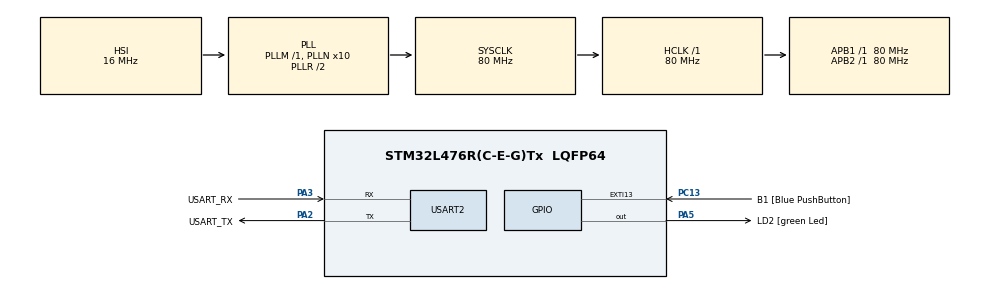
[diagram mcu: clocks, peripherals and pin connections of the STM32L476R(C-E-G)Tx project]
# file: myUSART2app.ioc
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Dma.Request0=USART2_RX
Dma.Request1=USART2_TX
Dma.USART2_RX.0.Direction=DMA_PERIPH_TO_MEMORY
Dma.USART2_RX.0.Instance=DMA1_Channel6
Dma.USART2_RX.0.MemDataAlignment=DMA_MDATAALIGN_BYTE
Dma.USART2_RX.0.MemInc=DMA_MINC_ENABLE
Dma.USART2_RX.0.Mode=DMA_NORMAL
Dma.USART2_RX.0.PeriphDataAlignment=DMA_PDATAALIGN_BYTE
Dma.USART2_RX.0.PeriphInc=DMA_PINC_DISABLE
Dma.USART2_RX.0.Priority=DMA_PRIORITY_LOW
Dma.USART2_TX.1.Direction=DMA_MEMORY_TO_PERIPH
Dma.USART2_TX.1.Instance=DMA1_Channel7
Dma.USART2_TX.1.MemDataAlignment=DMA_MDATAALIGN_BYTE
Dma.USART2_TX.1.MemInc=DMA_MINC_ENABLE
Dma.USART2_TX.1.Mode=DMA_NORMAL
Dma.USART2_TX.1.PeriphDataAlignment=DMA_PDATAALIGN_BYTE
Dma.USART2_TX.1.PeriphInc=DMA_PINC_DISABLE
Dma.USART2_TX.1.Priority=DMA_PRIORITY_LOW
Mcu.Family=STM32L4
Mcu.Name=STM32L476R(C-E-G)Tx
Mcu.Package=LQFP64
NVIC.DMA1_Channel6_IRQn=true\:0\:0\:false\:false\:true\:false\:true
NVIC.DMA1_Channel7_IRQn=true\:0\:0\:false\:false\:true\:false\:true
NVIC.PriorityGroup=NVIC_PRIORITYGROUP_4
NVIC.USART2_IRQn=true\:0\:0\:false\:false\:true\:true\:true
PA13\ (JTMS-SWDIO).GPIO_Label=TMS
PA13\ (JTMS-SWDIO).Mode=Serial_Wire
PA13\ (JTMS-SWDIO).Signal=SYS_JTMS-SWDIO
PA14\ (JTCK-SWCLK).GPIO_Label=TCK
PA14\ (JTCK-SWCLK).Mode=Serial_Wire
PA14\ (JTCK-SWCLK).Signal=SYS_JTCK-SWCLK
PA2.GPIO_Label=USART_TX
PA2.GPIO_Mode=GPIO_MODE_AF_PP
PA2.GPIO_PuPd=GPIO_NOPULL
PA2.GPIO_Speed=GPIO_SPEED_FREQ_VERY_HIGH
PA2.Mode=Asynchronous
PA2.Signal=USART2_TX
PA3.GPIO_Label=USART_RX
PA3.GPIO_Mode=GPIO_MODE_AF_PP
PA3.GPIO_PuPd=GPIO_NOPULL
PA3.GPIO_Speed=GPIO_SPEED_FREQ_VERY_HIGH
PA3.Mode=Asynchronous
PA3.Signal=USART2_RX
PA5.GPIO_Label=LD2 [green Led]
PA5.GPIO_ModeDefaultOutputPP=GPIO_MODE_OUTPUT_PP
PA5.GPIO_PuPd=GPIO_NOPULL
PA5.GPIO_Speed=GPIO_SPEED_FREQ_LOW
PA5.Signal=GPIO_Output
PB3\ (JTDO-TRACESWO).GPIO_Label=SWO
PB3\ (JTDO-TRACESWO).Signal=SYS_JTDO-SWO
PC13.GPIO_Label=B1 [Blue PushButton]
PC13.GPIO_ModeDefaultEXTI=GPIO_MODE_IT_FALLING
PC13.GPIO_PuPd=GPIO_NOPULL
PC13.Signal=GPXTI13
PC14-OSC32_IN\ (PC14).Mode=LSE-External-Oscillator
PC14-OSC32_IN\ (PC14).Signal=RCC_OSC32_IN
PC15-OSC32_OUT\ (PC15).Mode=LSE-External-Oscillator
PC15-OSC32_OUT\ (PC15).Signal=RCC_OSC32_OUT
PH0-OSC_IN\ (PH0).Signal=RCC_OSC_IN
PH1-OSC_OUT\ (PH1).Signal=RCC_OSC_OUT
ProjectManager.HeapSize=0x200
ProjectManager.StackSize=0x400
ProjectManager.TargetToolchain=SW4STM32
RCC.ADCFreq_Value=64000000
RCC.AHBFreq_Value=80000000
RCC.APB1Freq_Value=80000000
RCC.APB1TimFreq_Value=80000000
RCC.APB2Freq_Value=80000000
RCC.APB2TimFreq_Value=80000000
RCC.CortexFreq_Value=80000000
RCC.HCLKFreq_Value=80000000
RCC.HSE_VALUE=8000000
RCC.HSI_VALUE=16000000
RCC.MSI_VALUE=4000000
RCC.PLLN=10
RCC.PLLSourceVirtual=RCC_PLLSOURCE_HSI
RCC.PREFETCH_ENABLE=1
RCC.SYSCLKFreq_VALUE=80000000
RCC.SYSCLKSource=RCC_SYSCLKSOURCE_PLLCLK
RCC.USBFreq_Value=64000000
RCC.VCOOutputFreq_Value=160000000
USART2.VirtualMode-Asynchronous=VM_ASYNC
board=NUCLEO-L476RG

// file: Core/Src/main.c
/* USER CODE BEGIN Header */
/**
  ******************************************************************************
  * @file           : main.c
  * @brief          : Escape the Island — Text RPG
  ******************************************************************************
  * Baud Rate = 115200
  ******************************************************************************
  */
/* USER CODE END Header */
#include "main.h"

/* USER CODE BEGIN Includes */
#include <string.h>
/* USER CODE END Includes */

/* USER CODE BEGIN PTD */

typedef enum { //keeps track of state
    STATE_MAIN_MENU = 0,
    STATE_CHAR_SELECT,
    STATE_DIFF_SELECT,
    STATE_EXPLORE,
    STATE_DIALOGUE,
    STATE_INVENTORY,
    STATE_PUZZLE,
	STATE_TRAVEL,
	STATE_JUNGLE,
	STATE_CAVE,
	STATE_COASTLINE,
	STATE_TOWER,
	STATE_BUNKER,
    STATE_GAME_OVER
} GameStateEnum;

typedef struct { //keeps track of status variables
    int8_t   health;        // 0-100, death at 0
    int8_t   fear;          // 0-100, collapse at 100
    int8_t   morale;        // 0-100, abandon at 0
    int8_t   starvation;    // 0-100, death at 100
    uint8_t  character;     // 0=Engineer 1=Medic 2=Survivalist 3=Skeptic
    uint8_t  difficulty;    // 0=Easy 1=Hard
    uint8_t  location;      // 0=Beach 1=Jungle 2=Cave 3=Coastline 4=Tower 5=Bunker
    uint8_t  day;
    uint8_t searches_done;
    uint8_t  inventory[8];  // 0=battery 1=wire 2=tools 3=map 4=rope 5=wood 6=knife 7=key
    uint16_t flags;
    uint8_t survivors[4]; // 1=present, 0=missing. 0=Engineer,1=Medic,2=Survivalist,3=Skeptic
    uint8_t notes[4];
    uint8_t  puzzles_solved;
    uint8_t puzzle_step;        // tracks progress through puzzle
    char    puzzle_input[8];    // stores player input
    uint8_t active_puzzle;      // 0=radio, 1=cave, 2=bunker
    GameStateEnum state;
    GameStateEnum prev_state;
    uint32_t rng_seed;
} GameState;

/* USER CODE END PTD */

/* USER CODE BEGIN PD */

#define FLAG_MET_ENGINEER    (1 << 0)
#define FLAG_MET_MEDIC       (1 << 1)
#define FLAG_MET_SURVIVALIST (1 << 2)
#define FLAG_MET_SKEPTIC     (1 << 3)
#define FLAG_FOUND_KEY       (1 << 4)
#define FLAG_FIRE_LIT        (1 << 5)
#define FLAG_RAFT_BUILT      (1 << 6)
#define FLAG_HIGH_FEAR       (1 << 7)
#define FLAG_ENGINEER_HINT  (1 << 8)

#define ITEM_BATTERY  0
#define ITEM_WIRE     1
#define ITEM_TOOLS    2
#define ITEM_MAP      3
#define ITEM_ROPE     4
#define ITEM_WOOD     5
#define ITEM_KNIFE    6
#define ITEM_KEY      7

/* USER CODE END PD */

UART_HandleTypeDef huart2;
DMA_HandleTypeDef hdma_usart2_rx;
DMA_HandleTypeDef hdma_usart2_tx;

/* USER CODE BEGIN PV */
volatile uint8_t dataAvail = 0;
char rx_buff[1];
GameState gs;
/* USER CODE END PV */

void SystemClock_Config(void);
static void MX_GPIO_Init(void);
static void MX_USART2_UART_Init(void);
static void MX_DMA_Init(void);
/* USER CODE BEGIN PFP */
void UART_print(const char *str);
void game_init(void);
void show_main_menu(void);
void show_char_select(void);
void show_diff_select(void);
void show_explore(void);
void show_inventory(void);
void search_wreckage(void);
void show_survivor_list(void);
void show_dialogue(uint8_t survivor);
void show_map(void);
void show_travel_menu(void);
void show_jungle(void);
void search_jungle(void);
void show_current_location(void);
void show_cave(void);
void search_cave(void);
void cave_deeper(void);
void show_coastline(void);
void search_shipwreck(void);
void build_signal_fire(void);
void show_ascii_game_over(void);
void check_death_conditions(void);
void night_event(void);
void show_notes(void);
void show_tower(void);
void show_bunker(void);
void puzzle_radio(void);
void puzzle_cave(void);
void puzzle_bunker(void);
void build_raft(void);
void try_escape(void);
void show_ascii_win(void);
void show_win(void);
void show_stats(void);
void demo_cheats(void);
extern int8_t clamp(int32_t val, int32_t min, int32_t max);
extern uint32_t asm_rng(uint32_t seed);
uint32_t next_rand(void);
/* USER CODE END PFP */

/* USER CODE BEGIN 0 */

void UART_print(const char *str){
//define print function to make printing easier
    HAL_UART_Transmit(&huart2, (uint8_t *)str, strlen(str), 10);
}
uint32_t next_rand(void)
{
    gs.rng_seed = asm_rng(gs.rng_seed);
    return gs.rng_seed;
}
void game_init(void){
	gs.health         = 100;
	gs.fear           = 0;
    gs.morale         = 75;
    gs.starvation     = 0;
    gs.character      = 0;
    gs.difficulty     = 0;
    gs.location       = 0;
    gs.day            = 1;
    gs.flags          = 0;
    gs.puzzles_solved = 0;
    gs.puzzle_step    = 0;
    gs.active_puzzle  = 0;
    gs.searches_done  = 0;
	gs.rng_seed       = 12345;
    memset(gs.survivors, 1, sizeof(gs.survivors));
    memset(gs.notes, 0, sizeof(gs.notes));
    memset(gs.puzzle_input, 0, sizeof(gs.puzzle_input));
    memset(gs.inventory, 0, sizeof(gs.inventory));
    gs.state          = STATE_MAIN_MENU;
    gs.prev_state     = STATE_MAIN_MENU;

}

void show_main_menu(void)
{
    UART_print("\r\n");
    UART_print("'########::'######:::'######:::::'###::::'########::'########:\r\n");
    UART_print(" ##.....::'##... ##:'##... ##:::'## ##::: ##.... ##: ##.....::\r\n");
    UART_print(" ##::::::: ##:::..:: ##:::..:::'##:. ##:: ##:::: ##: ##:::::::\r\n");
    UART_print(" ######:::. ######:: ##:::::::'##:::. ##: ########:: ######:::\r\n");
    UART_print(" ##...:::::..... ##: ##::::::: #########: ##.....::: ##...::::\r\n");
    UART_print(" ##:::::::'##::: ##: ##::: ##: ##.... ##: ##:::::::: ##:::::::\r\n");
    UART_print(" ########:. ######::. ######:: ##:::: ##: ##:::::::: ########:\r\n");
    UART_print("........:::......::::......:::..:::::..::..:::::::::........::\r\n");
    UART_print("'########:'##::::'##:'########::::\r\n");
    UART_print("... ##..:: ##:::: ##: ##.....::::::\r\n");
    UART_print("::: ##:::: ##:::: ##: ##::::::::::\r\n");
    UART_print("::: ##:::: #########: ######::::::\r\n");
    UART_print("::: ##:::: ##.... ##: ##...::::::::\r\n");
    UART_print("::: ##:::: ##:::: ##: ##::::::::::\r\n");
    UART_print("::: ##:::: ##:::: ##: ########::::\r\n");
    UART_print(":::..:::::..:::::..::........:::::\r\n");
    UART_print("'####::'######::'##::::::::::'###::::'##::: ##:'########::\r\n");
    UART_print(". ##::'##... ##: ##:::::::::'## ##::: ###:: ##: ##.... ##:\r\n");
    UART_print(": ##:: ##:::..:: ##::::::::'##:. ##:: ####: ##: ##:::: ##:\r\n");
    UART_print(": ##::. ######:: ##:::::::'##:::. ##: ## ## ##: ##:::: ##:\r\n");
    UART_print(": ##:::..... ##: ##::::::: #########: ##. ####: ##:::: ##:\r\n");
    UART_print(": ##::'##::: ##: ##::::::: ##.... ##: ##:. ###: ##:::: ##:\r\n");
    UART_print("'####:. ######:: ########: ##:::: ##: ##::. ##: ########::\r\n");
    UART_print("....:::......:::........::..:::::..::..::::..::........:::\r\n");
    UART_print("\r\n");
    UART_print("  [P] Play\r\n");
    UART_print("  [X] Exit\r\n");
    UART_print("\r\n> ");
}

void show_char_select(void){
    UART_print("\r\n-- Choose your survivor --\r\n\r\n");
    UART_print("  [1] Engineer    - better puzzle outcomes\r\n");
    UART_print("  [2] Medic       - starts with higher health\r\n");
    UART_print("  [3] Survivalist - better resource finds\r\n");
    UART_print("  [4] Skeptic     - reduced morale for others\r\n");
    UART_print("\r\n> ");
}

void show_diff_select(void){
    UART_print("\r\n-- Choose difficulty --\r\n\r\n");
    UART_print("  [E] Easy - hints enabled, more resources\r\n");
    UART_print("  [H] Hard - fewer hints, lower health, lower morale\r\n");
    UART_print("\r\n> ");
}

void show_explore(void){
    UART_print("\r\n== BEACH ==\r\n");
    if (gs.fear < 34) {
        UART_print("Warm sand stretches around you. Survivors tend a small fire.\r\n");
    } else if (gs.fear < 67) {
        UART_print("The beach feels exposed. Every sound makes you flinch.\r\n");
    } else {
        UART_print("The waves sound wrong. The other survivors won't meet your eyes.\r\n");
    }
    UART_print("\r\n  [1] Search wreckage\r\n");
    UART_print("  [2] Talk to survivors\r\n");
    UART_print("  [3] View map\r\n");
    UART_print("  [4] View inventory\r\n");
    UART_print("  [5] Rest (advance day)\r\n");
    UART_print("  [6] Travel to another location\r\n");
    UART_print("  [7] Read notes\r\n");
    UART_print("  [8] Check stats\r\n");
    UART_print("\r\n> ");
}
void show_inventory(void){
	const char *item_names[8] ={
			"Battery", "Wire", "Tool Kit", "Map",
	"Rope", "Wood", "Knife", "Old Key"
	};
	UART_print("\r\n--Inventory--\r\n");
	uint8_t empty = 1;
	for (int i=0; i<8; i++){
		if (gs.inventory[i]){
			UART_print("[X]");
			UART_print(item_names[i]);
			UART_print("\r\n");
			empty=0;
		}
	}
	if (empty) UART_print("Nothing in Inventory yet.\r\n");
	UART_print("\r\nPress any key to continue...\r\n");
}
void search_wreckage(void){
	uint8_t roll = next_rand()%3; //assembly rng
	if (gs.inventory[ITEM_BATTERY] && gs.inventory[ITEM_WIRE] && gs.inventory[ITEM_TOOLS]) {
	    UART_print("\r\nThe wreckage has been picked clean. Nothing left.\r\n");
	}
	else if (gs.inventory[roll]){
		UART_print("\r\nYou dig through the wreckage but find nothing new.\r\n");
		gs.searches_done++;
	}
	else {
		const char *item_names[3] ={"Battery", "Wire", "Tool Kit"};
		gs.inventory[roll] =1;
		UART_print("\r\nYou found: ");
		UART_print(item_names[roll]);
		UART_print("!\r\n");
		gs.searches_done++;
	}
	gs.day++; //Searching takes up entire day
	UART_print("\r\nPress any key to continue...\r\n");
}
void show_survivor_list(void){
	UART_print("\r\n-- Survivors --\r\n\r\n");
	if (gs.survivors[0]) UART_print("  [1] Engineer\r\n");
	if (gs.survivors[1]) UART_print("  [2] Medic\r\n");
	if (gs.survivors[2]) UART_print("  [3] Survivalist\r\n");
	if (gs.survivors[3]) UART_print("  [4] Skeptic\r\n");
	UART_print("\r\n> ");
}
void show_dialogue(uint8_t survivor){
	if (!gs.survivors[survivor]) {
	UART_print("\r\nThat survivor is no longer here.\r\n");
	UART_print("\r\nPress any key to continue...\r\n");
	return;
	}
	switch(survivor){
		case 0: //Engineer
			gs.flags |=FLAG_MET_ENGINEER; //bitwise OR. met engineer flag bit=1
			if (gs.character == 0) {
			    UART_print("\r\nEngineer: \"Another engineer? Good. Don't get in my way.\"\r\n");
			}
			else if (gs.puzzles_solved & 0x01) {
				UART_print("\r\nEngineer: \"Good work on the radio. We might actually get out of here.\"\r\n");
			}
			else if ((gs.difficulty == 1) && (gs.flags & FLAG_FOUND_KEY)) {
				gs.flags |= FLAG_ENGINEER_HINT;
				UART_print("\r\nEngineer: \"If we can find a battery and some wire, I can fix the radio tower.\"\r\n");
				UART_print("Engineer: \"The panel has four wires. Blue carries the signal.\"\r\n");
				UART_print("Engineer: \"Red grounds the charge. Yellow is the warning wire.\"\r\n");
				UART_print("Engineer: \"Green completes the loop. Get the order right or it'll short out.\"\r\n");
			}
			else if ((gs.difficulty == 0) && (gs.flags & FLAG_FOUND_KEY)){ //only gives hint if on easy mode
				UART_print(("\r\nEngineer: \"That key you found... I think it opens something near the bunker.\"\r\n"));
			}
			else {
				UART_print("\r\nEngineer: \"If we can find a battery and some wire, I can fix the radio tower.\"\r\n");
			}
			break;
		case 1: //Medic
			gs.flags |= FLAG_MET_MEDIC;
			if (gs.character == 1) {
			     UART_print("\r\nMedic: \"I don't have enough supplies for both of us. Please be careful.\"\r\n");
			}
			else {
				gs.health += 10; //medic undoes damage
				gs.health = clamp(gs.health, 0, 100);//limit health to 100
				UART_print("\r\nMedic: \"Hold still... I'll patch you up.\"\r\n");
				UART_print("Your health increased.\r\n");
			}
			break;
		case 2: //Survivalist
			gs.flags |= FLAG_MET_SURVIVALIST;
			if (gs.character == 2){
				UART_print("\r\nSurvivalist: \"You know as well as I do.. jungle has rope and wood. Stop wasting time. We need to build a raft.\"\r\n");
			}
			else if (gs.flags & FLAG_RAFT_BUILT){
				UART_print("\r\nSurvivalist: \"The raft is ready. Say the word and we leave.\"\r\n");
			}
			else {
				UART_print("\r\nSurvivalist: \"We need rope and wood to build a raft. I've seen both in the jungle.\"\r\n");
			}
			break;
		 case 3: // Skeptic
		    gs.flags |= FLAG_MET_SKEPTIC;
		    if (gs.character == 3) {
		        UART_print("\r\nSkeptic: \"At least you're honest about our situation. Everyone else is delusional.\"\r\n");
		    }
		    else {
		        gs.morale -= 10;
		        gs.morale = clamp(gs.morale, 0, 100);
		        UART_print("\r\nSkeptic: \"Nobody is coming for us. We're going to die here.\"\r\n");
		        UART_print("Morale decreased.\r\n");
		        }
		    break;
	}
}
void show_map(void)
{
    UART_print("\r\n");
    UART_print("  ==========================================\r\n");
    UART_print("              I S L A N D   M A P\r\n");
    UART_print("  ==========================================\r\n");
    UART_print("\r\n    ");
    uint8_t jungle_has_items = (!gs.inventory[ITEM_ROPE] || !gs.inventory[ITEM_WOOD]);
    UART_print(gs.location == 1 ? "[JUNGLE*" : "[JUNGLE");
    UART_print(jungle_has_items ? "!]" : "]");
    UART_print("----------");
    UART_print(gs.location == 4 ? "[TOWER*]" : "[TOWER] ");
    UART_print("\r\n");
    UART_print("        |                    |\r\n");
    UART_print("        |      (ISLAND)      |\r\n");
    UART_print("        |                    |\r\n");
    UART_print("    ");
    uint8_t beach_has_items = (!gs.inventory[ITEM_BATTERY] || !gs.inventory[ITEM_WIRE] || !gs.inventory[ITEM_TOOLS]);
    UART_print(gs.location == 0 ? "[BEACH* " : "[BEACH");
    UART_print(beach_has_items ? "!]" : " ]");
    UART_print("----");
    uint8_t coast_has_items = (!gs.inventory[ITEM_KNIFE] || !gs.inventory[ITEM_MAP]);
    UART_print(gs.location == 3 ? "[COAST*" : "[COAST");
    UART_print(coast_has_items ? "!]" : "]");
    UART_print("----");
    uint8_t cave_has_items = (!gs.inventory[ITEM_KEY]);
    UART_print(gs.location == 2 ? "[CAVE*" : "[CAVE");
    UART_print(cave_has_items ? "!]" : "]");
    UART_print("\r\n");
    UART_print("                             |\r\n");
    UART_print("                         ");
    UART_print(gs.location == 5 ? "[BUNKER*]" : "[BUNKER] ");
    UART_print("\r\n");
    UART_print("\r\n  ==========================================\r\n");
    UART_print("  * = you are here\r\n");
    UART_print("  ! = items available\r\n");
    UART_print("  ==========================================\r\n");
    const char *loc_names[6] = {
        "BEACH", "JUNGLE", "CAVE", "COASTLINE", "RADIO TOWER", "BUNKER"
    };
    UART_print("  Location : ");
    UART_print(loc_names[gs.location]);
    UART_print("\r\n  Day      : ");
    char daybuf[4];
    daybuf[0] = '0' + (gs.day / 10);
    daybuf[1] = '0' + (gs.day % 10);
    daybuf[2] = '\0';
    UART_print(daybuf);
    UART_print("\r\n  ==========================================\r\n");
    UART_print("\r\nPress any key to continue...\r\n");
}
void show_travel_menu(void){
	//if current location -> print (you are here)
	UART_print("\r\n-- Where do you want to go? --\r\n\r\n");
	UART_print(gs.location == 0 ? "  [1] Beach (you are here)\r\n" : "  [1] Beach\r\n");
	UART_print(gs.location == 1 ? "  [2] Jungle (you are here)\r\n" : "  [2] Jungle\r\n");
	UART_print(gs.location == 2 ? "  [3] Cave (you are here)\r\n" : "  [3] Cave\r\n");
	UART_print(gs.location == 3 ? "  [4] Coastline (you are here)\r\n" : "  [4] Coastline\r\n");
	if (gs.inventory[ITEM_MAP])
	        UART_print(gs.location == 4 ? "  [5] Radio Tower (you are here)\r\n" : "  [5] Radio Tower\r\n");
	if (gs.inventory[ITEM_KEY])
	        UART_print(gs.location == 5 ? "  [6] Bunker (you are here)\r\n" : "  [6] Bunker\r\n");
	UART_print("\r\n> ");
}
void show_jungle(void){
    UART_print("\r\n== JUNGLE ==\r\n");
    if (gs.fear < 34) {
        UART_print("Thick canopy filters the sunlight. Birds call in the distance.\r\n");
    }
    else if (gs.fear < 67) {
        UART_print("The jungle feels like it's watching you. Every rustle makes you tense.\r\n");
    }
    else {
        UART_print("The trees press in around you. Something is out there. You're sure of it.\r\n");
    }
    UART_print("\r\n  [1] Search for materials\r\n");
    UART_print("  [2] Hunt for food\r\n");
    UART_print("  [3] View map\r\n");
    UART_print("  [4] View inventory\r\n");
    UART_print("  [5] Travel\r\n");
    UART_print("  [6] Rest (advance day)\r\n");
    UART_print("  [7] Read notes\r\n");
    UART_print("  [8] Check stats\r\n");
    UART_print("\r\n> ");
}
void search_jungle(void){
	uint8_t roll = next_rand()%2; //gives 0 or 1
	uint8_t item = roll+4; //Jungle items: items 4 & 5
	if (gs.inventory[item]){
		UART_print("\r\nYou search but find nothing new.\r\n");
	}
	else{
		const char *item_names[2] = {"Rope", "Wood"};
		        gs.inventory[item] = 1; //set item to found
		        UART_print("\r\nYou find: ");
		        UART_print(item_names[roll]);
		        UART_print("!\r\n");
	}
	gs.day++;
	UART_print("\r\nPress any key to continue...\r\n");
}
void hunt_jungle(void)
{
    uint8_t roll = next_rand() % 3; // 0,1 = success, 2 = nothing
    if (roll < 2) {
        gs.starvation -= 20;
        gs.starvation = clamp(gs.starvation, 0, 100);
        UART_print("\r\nYou catch a small animal and eat well.\r\n");
        UART_print("Starvation decreased.\r\n");
    } else {
        UART_print("\r\nYou find nothing to hunt today.\r\n");
    }
    gs.day++;
    UART_print("\r\nPress any key to continue...\r\n");
}
void show_current_location(void){
    switch(gs.location){
        case 0: show_explore();    break;
        case 1: show_jungle();     break;
        case 2: show_cave();    break;
        case 3: show_coastline();    break;
        case 4: show_tower();   break;
        case 5: show_bunker();  break;
    }
}
void show_cave(void){
	UART_print("\r\n== CAVE ==\r\n");
	if (gs.fear < 34) {
	    UART_print("A cave entrance waits ahead. Cool air drifts from within.\r\n");
	}
	else if (gs.fear < 67) {
	    UART_print("The cave is darker than you remembered. Your torch flickers.\r\n");
	}
	else {
	    UART_print("Something breathes in the dark. You tell yourself it's the wind.\r\n");
	}
	UART_print("\r\n  [1] Search the cave\r\n");
	UART_print("  [2] Go deeper\r\n");
	UART_print("  [3] View map\r\n");
	UART_print("  [4] View inventory\r\n");
	UART_print("  [5] Travel\r\n");
	UART_print("  [6] Rest (advance day)\r\n");
	UART_print("  [7] Read notes\r\n");
	UART_print("  [8] Check stats\r\n");
	UART_print("\r\n> ");
}
void search_cave(void){
	if (gs.inventory[ITEM_KEY]){
		UART_print("\r\nYou've already found everything useful here.\r\n");
	}
	else {
		gs.inventory[ITEM_KEY]=1;
		gs.flags |= FLAG_FOUND_KEY;
		UART_print("\r\nHidden beneath the rocks lies a rusty old key... as if waiting to be found.\r\n");
		UART_print("\r\n You pocket the key, a faint chill following your touch\r\n");
	}
	gs.day++;
	UART_print("\r\nPress any key to continue...\r\n");
}
void cave_deeper(void){
	gs.fear += 10;
	gs.fear = clamp(gs.fear, 0, 100);
	UART_print("\r\nYou descend deeper into the cave.\r\n");
	UART_print("The walls tighten around you. The air thins.\r\n");
	UART_print("A chamber waits ahead, its only passage buried in rubble.\r\n");
	puzzle_cave();
}
void show_coastline(void){
    UART_print("\r\n== COASTLINE ==\r\n");
    if (gs.fear < 34) {
        UART_print("Waves crash against jagged rocks. You spot a shipwreck off in the distance.\r\n");
    }
    else if (gs.fear < 67) {
        UART_print("The tide is coming in fast. The shipwreck groans in the current.\r\n");
    }
    else{
        UART_print("The ocean stretches endlessly. No ships. No planes. Nothing is coming.\r\n");
    }
    UART_print("\r\n  [1] Search the shipwreck\r\n");
    UART_print("  [2] Build signal fire\r\n");
    UART_print("  [3] View map\r\n");
    UART_print("  [4] View inventory\r\n");
    UART_print("  [5] Travel\r\n");
    UART_print("  [6] Read notes\r\n");
    UART_print("  [7] Build Raft\r\n");
    UART_print("  [8] Try to escape\r\n");
    UART_print("  [9] Check stats\r\n");
    UART_print("\r\n> ");
}
void search_shipwreck(void){
    uint8_t roll = next_rand() % 2; // 0 or 1
    if (gs.inventory[6] && gs.inventory[ITEM_MAP]) {
        UART_print("\r\nThe shipwreck has nothing left to offer.\r\n");
    }
    else {
        if (roll == 0 && !gs.inventory[ITEM_KNIFE]) {
            gs.inventory[ITEM_KNIFE] = 1;
            UART_print("\r\nYou find a Knife wedged in the hull.\r\n");
        }
        else if (roll == 1 && !gs.inventory[ITEM_MAP]) {
            gs.inventory[ITEM_MAP] = 1;
            UART_print("\r\nYou find a waterlogged Map. Still readable.\r\n");
        }
        else {
            UART_print("\r\nYou search but find nothing new this time.\r\n");
        }
    }
    gs.day++;
    UART_print("\r\nPress any key to continue...\r\n");
}
void build_signal_fire(void){
    if (!(gs.flags & FLAG_FIRE_LIT)) {
        gs.flags |= FLAG_FIRE_LIT;
        gs.morale += 15;
        gs.morale = clamp(gs.morale, 0, 100);
        UART_print("\r\nYou gather driftwood and light a signal fire.\r\n");
        UART_print("Smoke rises into the sky. Someone might see it.\r\n");
        UART_print("Morale increased.\r\n");
    }
    else {
        UART_print("\r\nThe signal fire is already burning.\r\n");
        UART_print("All you can do now is wait and hope.\r\n");
    }
    gs.day++;
    UART_print("\r\nPress any key to continue...\r\n");
}
void show_ascii_game_over(void)
{
    UART_print("\r\n");
    UART_print(":'######::::::'###::::'##::::'##:'########:\r\n");
    UART_print("'##... ##::::'## ##::: ###::'###: ##.....::\r\n");
    UART_print(" ##:::..::::'##:. ##:: ####'####: ##:::::::\r\n");
    UART_print(" ##::'####:'##:::. ##: ## ### ##: ######:::\r\n");
    UART_print(" ##::: ##:: #########: ##. #: ##: ##...::::\r\n");
    UART_print(" ##::: ##:: ##.... ##: ##:.:: ##: ##:::::::\r\n");
    UART_print(". ######::: ##:::: ##: ##:::: ##: ########:\r\n");
    UART_print(":......::::..:::::..::..:::::..::........::\r\n");
    UART_print(":'#######::'##::::'##:'########:'########::\r\n");
    UART_print("'##.... ##: ##:::: ##: ##.....::: ##.... ##:\r\n");
    UART_print(" ##:::: ##: ##:::: ##: ##::::::::: ##:::: ##:\r\n");
    UART_print(" ##:::: ##: ##:::: ##: ######::::: ########::\r\n");
    UART_print(" ##:::: ##:. ##:: ##:: ##...:::::: ##.. ##:::\r\n");
    UART_print(" ##:::: ##::. ## ##::: ##::::::::: ##::. ##::\r\n");
    UART_print(". #######::::. ###:::: ########::: ##:::. ##:\r\n");
    UART_print(":.......::::::...:::::........::::..:::::..:\r\n");
    UART_print("\r\n");
}
void check_death_conditions(void){
    if (gs.health <= 0) {
        UART_print("YOU DIED. \r\n");
        UART_print("Your injuries were too severe.\r\n");
        UART_print("Press reset to play again.\r\n");
        show_ascii_game_over();
        while(1);
    }
    if (gs.fear >= 100) {
        UART_print("PSYCHOLOGICAL COLLAPSE. \r\n");
        UART_print("The island broke you. You gave up.\r\n");
        UART_print("Press reset to play again.\r\n");
        show_ascii_game_over();
        while(1);
    }
    if (gs.morale <= 0) {
        UART_print("ABANDONED \r\n");
        UART_print("The group fell apart. You were left behind.\r\n");
        UART_print("Press reset to play again.\r\n");
        show_ascii_game_over();
        while(1);
    }
}
void night_event(void){
    uint8_t roll = next_rand()% 6;
    UART_print("\r\n-- Night falls --\r\n\r\n");
    switch(roll)
    {
        case 0: // Storm
            gs.fear += 15;
            gs.fear = clamp(gs.fear, 0, 100);
            UART_print("A violent storm rolls in. Lightning splits the sky.\r\n");
            UART_print("Fear increased.\r\n");
            break;
        case 1: // Animal attack
            gs.health -= 15;
            gs.fear += 10;
            gs.fear = clamp(gs.fear, 0, 100);
            gs.health = clamp(gs.health, 0, 100);
            UART_print("Something attacks your camp in the night.\r\n");
            UART_print("You fight it off but take injuries.\r\n");
            UART_print("Health decreased. Fear increased.\r\n");
            break;
        case 2: // Footsteps
            gs.fear += 20;
            gs.fear = clamp(gs.fear, 0, 100);
            UART_print("You hear footsteps circling the camp.\r\n");
            UART_print("By morning, whoever it was is gone.\r\n");
            UART_print("Fear increased.\r\n");
            break;
        case 3: // Survivor missing
        {
            uint8_t victim = next_rand() % 4;
            gs.survivors[victim] = 0;
            gs.notes[victim] = 1;
            gs.morale -= 20;
            gs.morale = clamp(gs.morale, 0, 100);
            UART_print("You wake to find one of the survivors gone.\r\n");
            // each victim leaves a note
            switch(victim)
            {
                case 0:
                    UART_print("You find a scrawled note:\r\n");
                    UART_print("'Battery + wire + tools = radio tower. --Engineer'\r\n");
                    break;
                case 1:
                    UART_print("You find a medical kit left behind with a note:\r\n");
                    UART_print("'Use this. Stay alive. --Medic'\r\n");
                    gs.health += 10;
                    gs.health = clamp(gs.health, 0, 100);
                    break;
                case 2:
                    UART_print("You find a note scratched into the sand:\r\n");
                    UART_print("'Rope + wood + knife = raft. Trust no one. --Survivalist'\r\n");
                    break;
                case 3:
                    UART_print("You find a note:\r\n");
                    UART_print("'We were never getting off this island. --Skeptic'\r\n");
                    gs.morale -= 10;
                    gs.morale = clamp(gs.morale, 0, 100);
                    break;
            }
            UART_print("Morale decreased.\r\n");
            break;
        }
        case 4: // Fire goes out
            if (gs.flags & FLAG_FIRE_LIT) {
                gs.flags &= ~FLAG_FIRE_LIT;
                gs.morale -= 10;
                gs.morale = clamp(gs.morale, 0, 100);
                UART_print("The signal fire went out in the night.\r\n");
                UART_print("Morale decreased.\r\n");
            }
            else {
                UART_print("A quiet night. You sleep better than expected.\r\n");
                gs.morale += 5;
                gs.morale = clamp(gs.morale, 0, 100);
            }
            break;
        case 5: // Peaceful night
            gs.morale += 10;
            gs.health += 5;
            gs.morale = clamp(gs.morale, 0, 100);
            gs.health = clamp(gs.health, 0, 100);
            UART_print("A rare peaceful night. The stars are beautiful.\r\n");
            UART_print("Health and morale increased.\r\n");
            break;
    }
    if (gs.fear >= 70) gs.flags |= FLAG_HIGH_FEAR;
    UART_print("\r\nPress any key to continue...\r\n");
    check_death_conditions();
}
void show_notes(void){
    UART_print("\r\n-- Notes --\r\n\r\n");
    uint8_t any = 0;
    if (gs.notes[0]) {
        UART_print("Engineer: 'Battery + wire + tools = radio tower.'\r\n");
        any = 1;
        if (gs.difficulty==1){
        	gs.flags |= FLAG_ENGINEER_HINT;
        	UART_print("When you get in: The panel has four wires. Blue carries the signal.\r\n");
        	UART_print("Red grounds the charge. Yellow is the warning wire.\r\n");
        	UART_print("Green completes the loop. Get the order right or it'll short out.\r\n");
        }
    }
    if (gs.notes[1]) {
        UART_print("Medic: 'Stay alive.'\r\n");
        any = 1;
    }
    if (gs.notes[2]) {
        UART_print("Survivalist: 'Rope + wood + knife = raft.'\r\n");
        any = 1;
    }
    if (gs.notes[3]) {
        UART_print("Skeptic: 'We were never getting off this island.'\r\n");
        any = 1;
    }
    if (!any) UART_print("No notes yet.\r\n");
    UART_print("\r\nPress any key to continue...\r\n");
}
void show_tower(void){
    UART_print("\r\n== RADIO TOWER ==\r\n");
    if (gs.fear < 34) {
        UART_print("A rusted radio tower rises above the trees. It might still work.\r\n");
    }
    else if (gs.fear < 67) {
        UART_print("The tower sways in the wind. Loose wires whip and dangle in every direction.\r\n");
    }
    else {
        UART_print("The tower looks like it could collapse any moment. Do you really want to climb it?\r\n");
    }
    UART_print("\r\n  [1] Attempt radio puzzle\r\n");
    UART_print("  [2] View map\r\n");
    UART_print("  [3] View inventory\r\n");
    UART_print("  [4] Read notes\r\n");
    UART_print("  [5] Travel\r\n");
    UART_print("  [6] Check stats\r\n");
    UART_print("\r\n> ");
}
void show_bunker(void){
    UART_print("\r\n== BUNKER ==\r\n");
    if (gs.fear < 34) {
        UART_print("A bunker door is built into the hillside. The key fits the lock.\r\n");
    } else if (gs.fear < 67) {
        UART_print("The bunker door is cold to the touch. Something hums inside.\r\n");
    } else {
        UART_print("You don't want to know what's in there, but what choice do you have?\r\n");
    }
    UART_print("\r\n  [1] Attempt generator puzzle\r\n");
    UART_print("  [2] View map\r\n");
    UART_print("  [3] View inventory\r\n");
    UART_print("  [4] Read notes\r\n");
    UART_print("  [5] Travel\r\n");
    UART_print("  [6] Check stats\r\n");
    UART_print("\r\n> ");
}
void puzzle_radio(void){
	if (gs.puzzles_solved & 0x01) {
	    UART_print("\r\nThe radio is already transmitting a signal.\r\n");
	    UART_print("\r\nPress any key to continue...\r\n");
	    gs.state = STATE_INVENTORY;
	    gs.prev_state = STATE_TOWER;
	    return;
	}
    // Check required items
	else if (!gs.inventory[ITEM_BATTERY] || !gs.inventory[ITEM_WIRE] ||
        !gs.inventory[ITEM_TOOLS]   || !gs.inventory[ITEM_MAP]) {
        UART_print("\r\nYou don't have everything you need.\r\n");
        UART_print("Required: Battery, Wire, Tool Kit, Map\r\n");
        UART_print("\r\nPress any key to continue...\r\n");
        gs.state = STATE_INVENTORY;
        gs.prev_state = STATE_TOWER;
        return;
    }

    UART_print("\r\n== RADIO TOWER PUZZLE ==\r\n");
    UART_print("The radio panel has four wire slots: R G B Y\r\n");
    UART_print("You need to connect them in the correct order.\r\n\r\n");
    if (gs.difficulty == 0) {
        UART_print("Four wires must be connected in order:\r\n\r\n");
        UART_print("  - Red is not last, but Blue comes before Red.\r\n");
        UART_print("  - Yellow comes after Red, but before Green.\r\n");
    }
    else {
        if(gs.character == 0){
    	    	UART_print("  - The wire that carries the signal starts the circuit.\r\n");
    	    	UART_print("  - The wire that grounds the charge follows immediately.\r\n");
    	    	UART_print("  - The warning wire comes third.\r\n");
    	    	UART_print("  - The wire that completes the loop is last.\r\n\r\n");
    	    	UART_print(" You recall that blue carries the signal, yellow is the warning wire, and red grounds the charge\r\n");
    	    	}
        else if (gs.flags & FLAG_ENGINEER_HINT) {
    	        UART_print("  - The wire that carries the signal starts the circuit.\r\n");
    	        UART_print("  - The wire that grounds the charge follows immediately.\r\n");
    	        UART_print("  - The warning wire comes third.\r\n");
    	        UART_print("  - The wire that completes the loop is last.\r\n\r\n");
    	        UART_print("Maybe the engineer's hint could be used to solve this..");
    	    }
    	else {
    	        UART_print("The panel is unlabeled. You'll need to figure this out yourself.\r\n");
    	        UART_print("Maybe someone on the island knows something...\r\n\r\n");
    	    }
    }
    UART_print("Enter the correct sequence (4 letters, e.g. BRGY):\r\n");
    UART_print("> ");
    // Switch to puzzle input mode
    gs.state = STATE_PUZZLE;
    gs.puzzle_step = 0;
    memset(gs.puzzle_input, 0, sizeof(gs.puzzle_input));
}
void puzzle_cave(void){
	if (gs.puzzles_solved & 0x02) {
	    UART_print("\r\nThe passage is already clear.\r\n");
	    UART_print("\r\nPress any key to continue...\r\n");
	    gs.state = STATE_INVENTORY;
	    gs.prev_state=STATE_CAVE;
	    return;
	}
	else if (!(gs.flags & FLAG_FOUND_KEY)) {
        UART_print("\r\nThe chamber is blocked. Search around some more, and try again later.\r\n");
        UART_print("\r\nPress any key to continue...\r\n");
        gs.state = STATE_INVENTORY;
        gs.prev_state = STATE_CAVE;
        return;
    }
    UART_print("\r\n== CAVE PUZZLE ==\r\n");
    UART_print("You squeeze into a sealed chamber.\r\n");
    UART_print("The air is thin. Debris blocks the passage ahead.\r\n\r\n");
    UART_print("Three piles block the way: A, B, and C.\r\n\r\n");
    if (gs.difficulty == 0) {
    	UART_print("A quick inspection reveals:\r\n");
    	UART_print("  - Pile C is behind Pile A.\r\n");
    	UART_print("  - Pile B is blocking access to Pile A.\r\n");
    	UART_print("  - Pile A must be cleared before anything behind it can shift.\r\n");
    }
    else {
        UART_print("The air grows thinner with every second you hesitate.\r\n");
        UART_print("The structural integrity is critical:\r\n");
        UART_print("  - Pile C is immovable while Pile A is in its current location.\r\n");
        UART_print("  - Pile A is structurally braced by the position of Pile B.\r\n");
        UART_print("  - Pile B is the only mass currently free of external load.\r\n\r\n");
    }
    UART_print("Which pile do you move first? (A/B/C):\r\n> ");
    gs.active_puzzle = 1;
    gs.puzzle_step = 0;
    gs.state = STATE_PUZZLE;
}
void puzzle_bunker(void){
	if (gs.puzzles_solved & 0x04) {
	    UART_print("\r\nThe generator is already running.\r\n");
	    UART_print("\r\nPress any key to continue...\r\n");
	    gs.state = STATE_INVENTORY;
	    gs.prev_state = STATE_BUNKER;
	    return;
	}
	else if (!gs.inventory[ITEM_BATTERY] || !gs.inventory[ITEM_WIRE]) {
        UART_print("\r\nThe generator needs power components.\r\n");
        UART_print("Required: Battery, Wire\r\n");
        UART_print("\r\nPress any key to continue...\r\n");
        gs.state = STATE_INVENTORY;
        gs.prev_state = STATE_BUNKER;
        return;
    }
    UART_print("\r\n== BUNKER PUZZLE ==\r\n");
    UART_print("A rusted generator sits in the corner.\r\n");
    UART_print("Three steps to get it running:\r\n\r\n");
    UART_print("  [1] Connect the battery\r\n");
    UART_print("  [2] Route the wiring\r\n");
    UART_print("  [3] Prime the fuel line\r\n\r\n");
    if (gs.difficulty == 0) {
        UART_print("Hint: Prime the fuel line before connecting anything.\r\n");
        UART_print("Connecting power before priming will short the system.\r\n\r\n");
    }
    else {
    	if (gs.character == 0){
    		UART_print("You recall you should always prime mechanical systems before applying power.\r\n\r\n");
    	}
        if (gs.flags & FLAG_ENGINEER_HINT) {
            UART_print("You recall the Engineer mentioning something about\r\n");
            UART_print("always priming mechanical systems before applying power.\r\n\r\n");
        }
        else {
            UART_print("The generator looks complex. Maybe someone on the\r\n");
            UART_print("island knows how these systems work...\r\n\r\n");
        }
    }
    UART_print("Choose your first step (1/2/3):\r\n> ");
    gs.active_puzzle = 2;
    gs.puzzle_step = 0;
    gs.state = STATE_PUZZLE;
}
void build_raft(void)
{
    if (!gs.inventory[ITEM_ROPE] || !gs.inventory[ITEM_WOOD] ||
        !gs.inventory[ITEM_KNIFE]) {
        UART_print("\r\nYou need Rope, Wood, and a Knife to build a raft.\r\n");
        UART_print("\r\nPress any key to continue...\r\n");
        return;
    }
    if (gs.flags & FLAG_RAFT_BUILT) {
        UART_print("\r\nThe raft is already built and waiting.\r\n");
        UART_print("\r\nPress any key to continue...\r\n");
        return;
    }
    if (!(gs.flags & FLAG_MET_SURVIVALIST)) {
        UART_print("\r\nYou don't know how to build a raft alone.\r\n");
        UART_print("Talk to the Survivalist first.\r\n");
        UART_print("\r\nPress any key to continue...\r\n");
        return;
    }
    gs.flags |= FLAG_RAFT_BUILT;
    gs.morale += 20;
    gs.morale = clamp(gs.morale, 0, 100);
    UART_print("\r\nYou spend the day building a raft.\r\n");
    UART_print("It's rough but it'll hold.\r\n");
    UART_print("Morale increased.\r\n");
    gs.day++;
    UART_print("\r\nPress any key to continue...\r\n");
}
void show_ascii_win(void)
{
    UART_print("\r\n");
    UART_print("'##:::'##::'#######::'##::::'##::::\r\n");
    UART_print(". ##:'##::'##.... ##: ##:::: ##::::\r\n");
    UART_print(":. ####::: ##:::: ##: ##:::: ##::::\r\n");
    UART_print("::. ##:::: ##:::: ##: ##:::: ##::::\r\n");
    UART_print("::: ##:::: ##:::: ##: ##:::: ##::::\r\n");
    UART_print("::: ##:::: ##:::: ##: ##:::: ##::::\r\n");
    UART_print("::: ##::::. #######::. #######:::::\r\n");
    UART_print(":::..::::::.......::::.......:::::\r\n");
    UART_print("'##:::::'##::'#######::'##::: ##:\r\n");
    UART_print(" ##:'##: ##:'##.... ##: ###:: ##:\r\n");
    UART_print(" ##: ##: ##: ##:::: ##: ####: ##:\r\n");
    UART_print(" ##: ##: ##: ##:::: ##: ## ## ##:\r\n");
    UART_print(" ##: ##: ##: ##:::: ##: ##. ####:\r\n");
    UART_print(" ##: ##: ##: ##:::: ##: ##:. ###:\r\n");
    UART_print(". ###. ###::. #######:: ##::. ##:\r\n");
    UART_print(":...::...::::.......:::..::::..:\r\n");
    UART_print("\r\n");
}
void show_win(void){
    show_ascii_win();
    UART_print("The radio signal brought the coordinates.\r\n");
    UART_print("The bunker beacon confirmed your position.\r\n");
    UART_print("The raft carried you to the rescue ship.\r\n\r\n");
    UART_print("Every decision. Every risk. Every sleepless night.\r\n");
    UART_print("It all led to this moment.\r\n\r\n");
    UART_print("The survivors who remain stand with you on the deck.\r\n");
    UART_print("Nobody speaks. Nobody needs to.\r\n\r\n");
    UART_print("Days survived: ");
    char daybuf[4];
    daybuf[0] = '0' + (gs.day / 10);
    daybuf[1] = '0' + (gs.day % 10);
    daybuf[2] = '\0';
    UART_print(daybuf);
    UART_print("\r\n");
    UART_print("\r\nSurvivors remaining: ");
    uint8_t count = 0;
    for (int i = 0; i < 4; i++) if (gs.survivors[i]) count++;
    char countbuf[2] = {'0' + count, '\0'};
    UART_print(countbuf);
    UART_print("/4\r\n");
    UART_print("\r\nPress reset to play again.\r\n");
    while(1);
}
void try_escape(void){
    // Check if all puzzles are solves
    if (!(gs.puzzles_solved & 0x01)) {
        UART_print("\r\nThe radio tower isn't fixed yet.\r\n");
        UART_print("\r\nPress any key to continue...\r\n");
        return;
    }
    if (!(gs.puzzles_solved & 0x02)) {
        UART_print("\r\nThe cave passage is still blocked.\r\n");
        UART_print("\r\nPress any key to continue...\r\n");
        return;
    }
    if (!(gs.puzzles_solved & 0x04)) {
        UART_print("\r\nThe bunker generator isn't running.\r\n");
        UART_print("\r\nPress any key to continue...\r\n");
        return;
    }
    // Check if raft built
    if (!(gs.flags & FLAG_RAFT_BUILT)) {
        UART_print("\r\nYou haven't built the raft yet.\r\n");
        UART_print("Required: Rope, Wood, Knife\r\n");
        UART_print("\r\nPress any key to continue...\r\n");
        return;
    }
    // Check morale
    uint8_t morale_threshold = (gs.difficulty == 0) ? 30 : 50;
    if (gs.morale < morale_threshold) {
        UART_print("\r\nThe group has lost the will to escape.\r\n");
        UART_print("Morale is too low. Rally the survivors first.\r\n");
        UART_print("\r\nPress any key to continue...\r\n");
        return;
    }
    show_win();
}
void show_stats(void)
{
    UART_print("\r\n-- Survivor Status --\r\n\r\n");
    UART_print("  Health     : ");
    char buf[4];
    if (gs.health >= 100) {
        UART_print("100");
    } else {
        buf[0] = '0' + (gs.health / 10);
        buf[1] = '0' + (gs.health % 10);
        buf[2] = '\0';
        UART_print(buf);
    }
    UART_print("/100\r\n");
    UART_print("  Fear       : ");
    buf[0] = '0' + (gs.fear / 10);
    buf[1] = '0' + (gs.fear % 10);
    UART_print(buf);
    UART_print("/100\r\n");
    UART_print("  Morale     : ");
    buf[0] = '0' + (gs.morale / 10);
    buf[1] = '0' + (gs.morale % 10);
    UART_print(buf);
    UART_print("/100\r\n");
    UART_print("  Starvation : ");
    buf[0] = '0' + (gs.starvation / 10);
    buf[1] = '0' + (gs.starvation % 10);
    UART_print(buf);
    UART_print("/100\r\n");
    UART_print("  Day        : ");
    buf[0] = '0' + (gs.day / 10);
    buf[1] = '0' + (gs.day % 10);
    UART_print(buf);
    UART_print("\r\n");
    UART_print("\r\n-- Survivors Present --\r\n");
    if (gs.survivors[0]) UART_print("  Engineer\r\n");
    if (gs.survivors[1]) UART_print("  Medic\r\n");
    if (gs.survivors[2]) UART_print("  Survivalist\r\n");
    if (gs.survivors[3]) UART_print("  Skeptic\r\n");

    UART_print("\r\nPress any key to continue...\r\n");
}
void demo_cheats(void){
	for (int i=0; i<8; i++){
		gs.inventory[i]=1;
	}
	gs.flags |= FLAG_FOUND_KEY;
	gs.flags |= FLAG_MET_SKEPTIC;
	gs.flags |= FLAG_MET_SURVIVALIST;
	gs.flags |= FLAG_MET_MEDIC;
	gs.flags |=FLAG_MET_ENGINEER;
	gs.flags |= FLAG_ENGINEER_HINT;
	gs.flags |= FLAG_FIRE_LIT;
	gs.flags |= FLAG_RAFT_BUILT;
	UART_print("\r\nAll items have been found.\r\n");
	UART_print("All characters have been met. \r\n");
	UART_print("All puzzles have been unlocked\r\n");
}

/* USER CODE END 0 */

int main(void)
{

  /* MCU Configuration--------------------------------------------------------*/

  /* Reset of all peripherals, Initializes the Flash interface and the Systick. */
  HAL_Init();

  /* Configure the system clock */
  SystemClock_Config();

  /* Initialize all configured peripherals */
  MX_GPIO_Init();
  MX_USART2_UART_Init();
  MX_DMA_Init();
  /* USER CODE BEGIN 2 */
  HAL_UART_Receive_IT(&huart2, (uint8_t *)rx_buff, 1);
  game_init();
  show_main_menu();
  /* USER CODE END 2 */

  /* Game engine runs in infinite loop until finished. */
  /* Game engine BEGIN WHILE */
  while(1)
  {
      if (!dataAvail) continue;

      char c = rx_buff[0]; //take char from UART buffer
      dataAvail = 0; //clear flag

      switch (gs.state)
      {
          case STATE_MAIN_MENU:
              if (c == 'p' || c == 'P') {
                  gs.state = STATE_CHAR_SELECT;
                  show_char_select();
              } else if (c == 'x' || c == 'X') {
                  UART_print("\r\nGoodbye. Press reset to play again.\r\n");
                  while(1);
              }
              break;

          case STATE_CHAR_SELECT:
              if (c >= '1' && c <= '4') {
                  gs.character = c - '1';
                  gs.state = STATE_DIFF_SELECT;
                  show_diff_select();
              }
              break;

          case STATE_DIFF_SELECT:
              if (c == 'e' || c == 'E') {
                  gs.difficulty = 0;
                  gs.state = STATE_EXPLORE;
                  show_explore();
              } else if (c == 'h' || c == 'H') {
                  gs.difficulty = 1;
                  gs.health = 75;
                  gs.morale = 50;
                  gs.fear   = 10;
                  gs.state = STATE_EXPLORE;
                  show_explore();
              }
              break;

          case STATE_EXPLORE:
        	  if (c == '1'){
        		  gs.prev_state = STATE_EXPLORE;
        		  gs.state = STATE_INVENTORY; //use to return to prev. state
        		  search_wreckage();
        	  }
        	  else if (c == '2'){
        		  gs.state = STATE_DIALOGUE;
        		  show_survivor_list();
        	  }
        	  else if (c == '3'){
        		  gs.prev_state = STATE_EXPLORE;
        		  gs.state = STATE_INVENTORY;
        		  show_map();
        	  }
        	  else if (c == '4'){
        		  gs.prev_state = STATE_EXPLORE;
        		  gs.state = STATE_INVENTORY;
        		  show_inventory();

        	  }
        	  else if (c == '5') {
        		  gs.prev_state = STATE_EXPLORE;
        		  gs.state = STATE_INVENTORY;
        		  gs.day++;
        		  night_event();
              }
        	  else if (c == '6'){
        		  gs.state = STATE_TRAVEL;
        		  show_travel_menu();
        	  }
        	  else if (c == '7'){
        		  gs.prev_state = STATE_EXPLORE;
        		  gs.state = STATE_INVENTORY;
        		  show_notes();
        	  }
        	  else if (c == '8'){
        		  gs.prev_state = STATE_EXPLORE;
        		  gs.state = STATE_INVENTORY;
        		  show_stats();
        	  }
        	  else if (c == 'd'){
        		  gs.prev_state = STATE_EXPLORE;
        		  gs.state = STATE_INVENTORY;
        		  demo_cheats();
        	  }
              break;
          case STATE_INVENTORY:
        	  //return to previous state
        	  gs.state = gs.prev_state;
        	  show_current_location();
        	  break;
          case STATE_DIALOGUE:
        	  if (c>='1' && c <= '4'){
        		  show_dialogue(c-'1');
        		  gs.state = STATE_INVENTORY;
        		  gs.prev_state = STATE_EXPLORE;
        	  }
        	  else if (c=='5'){ //Leave
        		  gs.state = STATE_EXPLORE;
        		  show_explore();
        	  }
        	  break;
          case STATE_TRAVEL:
        	  if (c=='1'){
        		  gs.location = 0; //beach
        		  gs.state = STATE_EXPLORE;
        		  show_explore();
        	  }
        	  else if (c == '2'){
        		  gs.location = 1; //Jungle
        		  gs.state = STATE_JUNGLE;
        		  show_jungle();
        	  }
        	  else if (c == '3'){
        		  gs.location = 2; //Cave
        		  gs.state = STATE_CAVE;
        		  show_cave();
        	  }
        	  else if (c == '4'){
        		  gs.location = 3; //Coastline
        		  gs.state = STATE_COASTLINE;
        		  show_coastline();
        	  }
        	  else if (c == '5' && gs.inventory[ITEM_MAP]) {
        	      gs.location = 4; //tower
        	      gs.state = STATE_TOWER;
        	      show_tower();
        	  }
        	  else if (c == '6' && gs.inventory[ITEM_KEY]) {
        	      gs.location = 5; //bunker
        	      gs.state = STATE_BUNKER;
        	      show_bunker();
        	  }
        	  break;
          case STATE_JUNGLE:
        	  if (c == '1'){ //search for materials
        		  gs.prev_state = STATE_JUNGLE;
        		  gs.state = STATE_INVENTORY;
        		  search_jungle();
        	  }
        	  else if (c == '2'){ //Hunt for food
        		  gs.prev_state = STATE_JUNGLE;
        		  gs.state = STATE_INVENTORY;
        		  hunt_jungle();
        	  }
        	  else if (c == '3'){ //view map
        		  gs.prev_state = STATE_JUNGLE;
        		  gs.state = STATE_INVENTORY;
        		  show_map();
        	  }
        	  else if (c == '4'){ //view inventory
        		  gs.prev_state = STATE_JUNGLE;
        		  gs.state = STATE_INVENTORY;
        		  show_inventory();
        	  }
        	  else if (c == '5'){//travel
        		  gs.state = STATE_TRAVEL;
        		  show_travel_menu();
        	  }
        	  else if (c == '6') {
        	      gs.prev_state = STATE_JUNGLE;
        	      gs.state = STATE_INVENTORY;
        	      gs.day++;
        	      night_event();
        	  }
        	  else if (c == '7') {
        	      gs.prev_state = STATE_JUNGLE;
        	      gs.state = STATE_INVENTORY;
        	      show_notes();
        	  }
        	  else if (c == '8'){
        	      gs.prev_state = STATE_JUNGLE;
        	      gs.state = STATE_INVENTORY;
        	      show_stats();
        	  }
        	  break;
          case STATE_CAVE:
        	  if (c == '1'){ //search  the cave
        		  gs.prev_state = STATE_CAVE;
        		  gs.state = STATE_INVENTORY;
        		  search_cave();
        	  }
        	  else if (c == '2'){ //go deeper
        		  gs.prev_state = STATE_CAVE;
        		  gs.state = STATE_INVENTORY;
        		  cave_deeper();
        	  }
        	  else if (c == '3'){ //view map
        		  gs.prev_state = STATE_CAVE;
        		  gs.state = STATE_INVENTORY;
        		  show_map();
        	  }
        	  else if (c == '4'){ //view inventory
        		  gs.prev_state = STATE_CAVE;
        		  gs.state = STATE_INVENTORY;
        		  show_inventory();
        	  }
        	  else if (c == '5'){ //travel
        		  gs.state = STATE_TRAVEL;
        		  show_travel_menu();
        	  }
        	  else if (c == '6') {
        	       gs.prev_state = STATE_CAVE;
        	       gs.state = STATE_INVENTORY;
        	       gs.day++;
        	       night_event();
        	  }
        	  else if (c == '7') {
        	       gs.prev_state = STATE_CAVE;
        	       gs.state = STATE_INVENTORY;
        	       show_notes();
        	  }
        	  else if (c == '8'){
        	       gs.prev_state = STATE_CAVE;
           		   gs.state = STATE_INVENTORY;
        	       show_stats();
        	  }
        	  break;
          case STATE_COASTLINE:
        	  if (c == '1'){ //search shipwreck
        		  gs.prev_state = STATE_COASTLINE;
        		  gs.state = STATE_INVENTORY;
        		  search_shipwreck();
        	  }
        	  else if (c == '2'){ //build signal fire
        		  gs.prev_state = STATE_COASTLINE;
        		  gs.state = STATE_INVENTORY;
        		  build_signal_fire();
        	  }
        	  else if (c == '3'){ //view map
        		  gs.prev_state = STATE_COASTLINE;
        		  gs.state = STATE_INVENTORY;
        		  show_map();
        	  }
        	  else if (c == '4'){ //view inventory
        		  gs.prev_state = STATE_COASTLINE;
        		  gs.state = STATE_INVENTORY;
        		  show_inventory();
        	  }
        	  else if (c == '5'){ //travel
        		  gs.state = STATE_TRAVEL;
        		  show_travel_menu();
        	  }
        	      else if (c == '6') {
        	      gs.prev_state = STATE_COASTLINE;
        	      gs.state = STATE_INVENTORY;
        	      show_notes();
        	  }
        	      else if ( c == '7'){
        	    	  gs.prev_state = STATE_COASTLINE;
        	    	  gs.state = STATE_INVENTORY;
        	    	  build_raft();

        	  }
        	      else if (c == '8'){
        	    	  gs.prev_state = STATE_COASTLINE;
        	    	  gs.state = STATE_INVENTORY;
        	    	  try_escape();
        	  }
        	      else if (c == '9'){
        	          gs.prev_state = STATE_COASTLINE;
        	          gs.state = STATE_INVENTORY;
        	          show_stats();
        	  }
        	  break;
          case STATE_TOWER:
              if (c == '1') {
                  gs.prev_state = STATE_TOWER;
                  gs.state = STATE_PUZZLE;
                  puzzle_radio();
              } else if (c == '2') {
                  gs.prev_state = STATE_TOWER;
                  gs.state = STATE_INVENTORY;
                  show_map();
              } else if (c == '3') {
                  gs.prev_state = STATE_TOWER;
                  gs.state = STATE_INVENTORY;
                  show_inventory();
              } else if (c == '4') {
                  gs.prev_state = STATE_TOWER;
                  gs.state = STATE_INVENTORY;
                  show_notes();
              } else if (c == '5') {
                  gs.state = STATE_TRAVEL;
                  show_travel_menu();
              }
              else if (c == '6'){
                   gs.prev_state = STATE_TOWER;
                   gs.state = STATE_INVENTORY;
                   show_stats();
              }
              break;

          case STATE_BUNKER:
              if (c == '1') {
                  gs.prev_state = STATE_BUNKER;
                  gs.state = STATE_PUZZLE;
                  puzzle_bunker();

              } else if (c == '2') {
                  gs.prev_state = STATE_BUNKER;
                  gs.state = STATE_INVENTORY;
                  show_map();
              } else if (c == '3') {
                  gs.prev_state = STATE_BUNKER;
                  gs.state = STATE_INVENTORY;
                  show_inventory();
              } else if (c == '4') {
                  gs.prev_state = STATE_BUNKER;
                  gs.state = STATE_INVENTORY;
                  show_notes();
              } else if (c == '5') {
                  gs.state = STATE_TRAVEL;
                  show_travel_menu();
              }
              else if (c == '6'){
                  gs.prev_state = STATE_BUNKER;
                  gs.state = STATE_INVENTORY;
                  show_stats();
              }
              break;
          case STATE_PUZZLE:
              if (gs.active_puzzle == 0){ //radio tower puzzle
                  // Echo the character back so player can see what they typed
                  char echo[2] = {c, '\0'};
                  UART_print(echo);
                  // Store input
                  gs.puzzle_input[gs.puzzle_step] = c;
                  gs.puzzle_step++;
                  if (gs.puzzle_step >= 4) {
                      UART_print("\r\n");
                      // Check answer
                      if ((gs.puzzle_input[0] == 'B' || gs.puzzle_input[0] == 'b') &&
                          (gs.puzzle_input[1] == 'R' || gs.puzzle_input[1] == 'r') &&
                          (gs.puzzle_input[2] == 'Y' || gs.puzzle_input[2] == 'y') &&
                          (gs.puzzle_input[3] == 'G' || gs.puzzle_input[3] == 'g')) {
                          // Correct
                          gs.puzzles_solved |= 0x01;
                          UART_print("\r\nThe radio crackles to life!\r\n");
                          UART_print("A voice cuts through the static:\r\n");
                          UART_print("\"...survivor signal received... coordinates locked...\"\r\n");
                          UART_print("\"...rescue team en route... hold your position...\"\r\n");
                          UART_print("\r\nYou solved the Radio puzzle!\r\n");
                          UART_print("\r\n");
                          UART_print("                                                                                                    \r\n");
                          UART_print("                                                                                                    \r\n");
                          UART_print("                       ...                                                ...                       \r\n");
                          UART_print("                      .=%%=.                                            .-%%=.                      \r\n");
                          UART_print("                     .*@@@%=.                                          .=%@@@#..                    \r\n");
                          UART_print("                   .-%@@@#.                                             ..#@@@%-.                   \r\n");
                          UART_print("                  .=%@@@=.                                                .=@@@%=.                  \r\n");
                          UART_print("                  -@@@%=.         .                              ..        .-%@@@=.                 \r\n");
                          UART_print("                 :@@@@-         .=%=.                         ..=%=..       .-@@@@:.                \r\n");
                          UART_print("                .%@@@-         .*@@@#:                       .:#@@@*..       .-@@@%.                \r\n");
                          UART_print("               .*@@@+.        .%@@@%..                        ..#@@@%.        .+@@@#.               \r\n");
                          UART_print("               -%@@#:        .%@@@*                             .*@@@%..       :#@@%-.              \r\n");
                          UART_print("              .*@@@+.       .*@@@+.           ..::::..           .+@@@*.       .=@@@*.              \r\n");
                          UART_print("              :#@@%-       .-%@@#:          .=#@@@@@@#=.         .:#@@%-.      .-%@@#:.             \r\n");
                          UART_print("             .-%@@#.       .+@@@+.         .%@@@@@@@@@@%.         .=@@@+.       .*@@%-.             \r\n");
                          UART_print("             .-@@@*.       .*@@%-         .@@@@@@@@@@@@@@.        .-%@@*..      .*@@@=.             \r\n");
                          UART_print("             .=@@@*        :*@@%:         .@@@@@@@@@@@@@@.        .:%@@*:       .+@@@=.             \r\n");
                          UART_print("             .-@@@*.       .*@@%-         .@@@@@@@@@@@@@@.        .-%@@*..      .*@@@=.             \r\n");
                          UART_print("             .-%@@*.       .+@@@=         .:@@@@@@@@@@@@:         .=%@@*.       .*@@@-.             \r\n");
                          UART_print("              :#@@#:       .=%@@*.         .-@@@@@@@@@@-.        ..*@@%=.      .:#@@#:.             \r\n");
                          UART_print("              .*@@%=.       .#@@@=.        .@@@+****=@@%.        .-@@@#.       .=%@@*.              \r\n");
                          UART_print("              .=%@@*.       .:@@@@-        -@@@=.  .-@@@-       .-%@@@:.       .*@@%=.              \r\n");
                          UART_print("               .#@@@-.       .:@@@@+.     .@@@@@%=-%@@@@%.     .+@@@@-.        -@@@#.               \r\n");
                          UART_print("                :@@@%.         :%@@@#:    -@@%-+@@@@+:%@@:   .:*@@@%-.        .%@@@-.               \r\n");
                          UART_print("                .=@@@%.         .*@#:    .#@@+:%@%%@%:+@@#.    :#@*:.       ..%@@@=.                \r\n");
                          UART_print("                  +@@@%:.        .:     .:%@@@@@+..+@@@@@%:     .:.        .:#@@@+.                 \r\n");
                          UART_print("                  .+@@@%:.              .+@@@@+.    .=@@@@+.              .:#@@@*..                 \r\n");
                          UART_print("                   .*@@@@-              :#@@#.       ..#@@#:             .-@@@@*.                   \r\n");
                          UART_print("                     -%@@@%:.          .-@@@@#-.    .-#@@@@=.          ..#@@@%-.                    \r\n");
                          UART_print("                      .*@@#:.          .*@@=+%@%-..-%@%+=@@*.          .:#@@#.                      \r\n");
                          UART_print("                       .::.            :@@@...=%@%#@@=...%@@:            .:-.                       \r\n");
                          UART_print("                                      .*@@+   ..@@@@..  .+@@*                                       \r\n");
                          UART_print("                                      .@@@- .:#@@++@@#:. :@@@.                                      \r\n");
                          UART_print("                                     .+@@*.:*@@*. ..*@@*:.*@@+.                                     \r\n");
                          UART_print("                                     .#@@*#@@*..    ..+%@#*@@%.                                     \r\n");
                          UART_print("                                    .+%@@@@*..        ..+@@@@@=                                     \r\n");
                          UART_print("                                    .*@@%*.              .+%@@*..                                   \r\n");
                          UART_print("                                   .-%@@#-.             ..-#@@%-.                                   \r\n");
                          UART_print("                                   .+@@%%@%+..       ...=%@%%@@+.                                   \r\n");
                          UART_print("                                   :%@@..-%@@#:.    .:*%@%-..@@%:                                   \r\n");
                          UART_print("                                   -@@%   ..*@@%-..-%@@*.   .%@@-                                   \r\n");
                          UART_print("                                  .%@@-     ..+%@%%@%+..     :@@%.                                  \r\n");
                          UART_print("                                 .-@@#:     ..-#@@@@#-.      .%@@-                                  \r\n");
                          UART_print("                                 .#@@=.    .=%@@+::+@@%=.    .=@@%.                                 \r\n");
                          UART_print("                                .:%@%-  ..*@@%-.    .-%@@*.  .-%@%:                                 \r\n");
                          UART_print("                                .*@@*..-#@@#:.        .:#@@#-..+@@#.                                \r\n");
                          UART_print("                               .:#@%+=%@%+.             ..+%@%==%@#:.                               \r\n");
                          UART_print("                               .=@@@%@#-....................-#@%@@@+.                               \r\n");
                          UART_print("                          .-#%%%@@@@@@@%%%%%%%%%%%%%%%%%%%%%%@@@@@@@%%%#-.                          \r\n");
                          UART_print("                         :%@@@@@@@@@@@@@@@@@@@@@@@@@@@@@@@@@@@@@@@@@@@@@@%:.                        \r\n");
                          UART_print("                        .#@@@@@@@@@@@@@@@@@@@@@@@@@@@@@@@@@@@@@@@@@@@@@@@@#.                        \r\n");
                          UART_print("                        .#@@@@@@@@@@@@@@@@@@@@@@@@@@@@@@@@@@@@@@@@@@@@@@@@%.                        \r\n");
                          UART_print("                        ....................................................                        \r\n");
                      }
                      else {
                          // Wrong
                          UART_print("\r\nSparks fly. Wrong sequence.\r\n");
                          gs.health -= 10;
                          if (gs.health <= 0) gs.health = 0;
                          UART_print("Health decreased.\r\n");
                      }
                      gs.puzzle_step = 0;
                      memset(gs.puzzle_input, 0, sizeof(gs.puzzle_input));
                      gs.state = STATE_TOWER;
                      UART_print("\r\nPress any key to continue...\r\n");
                      gs.state = STATE_INVENTORY;
                      gs.prev_state = STATE_TOWER;
                      check_death_conditions();
                  }
              }
              else if (gs.active_puzzle == 1){ //cave puzzle
                  char echo[2] = {c, '\0'};
                  UART_print(echo);
                  UART_print("\r\n");
                  const char correct[3] = {'B', 'A', 'C'};
                  if (c == correct[gs.puzzle_step] || c == correct[gs.puzzle_step] + 32) {
                      // Correct choice
                      gs.puzzle_step++;
                      if (gs.puzzle_step == 1) UART_print("You clear pile B. The passage opens slightly.\r\n");
                      if (gs.puzzle_step == 2) UART_print("You heave pile A aside. Almost through.\r\n");
                      if (gs.puzzle_step == 3) {
                          // Solved
                          gs.puzzles_solved |= 0x02;
                          UART_print("You carefully remove pile C. The passage is clear!\r\n");
                          UART_print("Fresh air rushes in. You crawl through to the other side.\r\n");
                          UART_print("You found an underground chamber with supplies.\r\n");
                          UART_print("\r\nYou solved the Cave puzzle!\r\n");
                          UART_print("                                                                                                    \r\n");
                          UART_print("                                                                                                    \r\n");
                          UART_print("                                               .....                                                \r\n");
                          UART_print("                                              -%@@@#-                                               \r\n");
                          UART_print("                                             =@@-.=%@+.                                             \r\n");
                          UART_print("                                            -%@-  .:@@+.                                            \r\n");
                          UART_print("                                          .:#@=     .%@@=..  ..=@%-.                                \r\n");
                          UART_print("                               ....       .+@*. .-:  .-@@-. .-%@#%@#:.                              \r\n");
                          UART_print("                              -%@%=.      -@%-. .+-. ..+@*..-@@-..+@#..                             \r\n");
                          UART_print("                            .=@%+#@%.     *@+.*..-:..%.-%@+*@@=...:#@=.                             \r\n");
                          UART_print("                            -@@-..*@#.   :@%-:@- .. :@-.#@@*#+.+*..=@%.                             \r\n");
                          UART_print("                           :%@+.  -@@*...#@#..:. ::..-..+@#.*.... .-@@@+.                           \r\n");
                          UART_print("                          .+@%..  -#+@@@@@@+.    -*: ...=@%..      :*-%@#.                          \r\n");
                          UART_print("                    :%+. .-%@:.   -* .+@%.#=.    ... ...+@%.:%@@@%:.=..%@=.                         \r\n");
                          UART_print("                   .=@%+..+@#..   := :#@-.#:         .-+-@@-@#:..%%:   *@+.                         \r\n");
                          UART_print("                   :#%:+*:#@-   ...  :%@:.+.         ..:.+@@@+.  *@---.*@+.                         \r\n");
                          UART_print("                  .-@#..=%@%:   :=:  :%@:     .-***-.     :%@*.  +@--+.=@#:.                        \r\n");
                          UART_print("                  .*@+-..*@*.   .*=  :%@:     *###@@=      .%%-  +@-::..=@@%*.                      \r\n");
                          UART_print("                  :@#:. .%@=.    ..  :%@:    .%@@@@@+      .+@*. *@+#%=....=@@*.                    \r\n");
                          UART_print("                  +@+.  :@%-#@@#.    :%@:    .%@@@@@+      .:%@@##@-. +*    .%@=.                   \r\n");
                          UART_print("                 .@%#@%.*@*#%..::   .-%@: := .%@@@@@+    .....:+%@@+. =*.    +@*.                   \r\n");
                          UART_print("               .-@@#--%@@#-##  ... .-%@+. -+..%@@@@@+   ......   :@%- ..     :@%:                   \r\n");
                          UART_print("               :%@+........## .....*@%-...-*..-%@@@#:.............#@=..      .#@*=.                 \r\n");
                          UART_print("               =@@. .+:.  .##..:=*%@+.............................=@*..      ..=*@@=.               \r\n");
                          UART_print("              .*@#  .:..-%@@@@@%@@%:.......-............:.........:%@@%*:.      .=@%:               \r\n");
                          UART_print("              :#@=     -@*.....-@*.   .:. :**%@@@@@@@@*.+-..=.   .:#=..*@@=.     :@@-               \r\n");
                          UART_print("             .-%@:     *@=.. .+@+.     -: :@@@@@@@@@@@%-**..+:.   .*-   .*@-     .@@+.              \r\n");
                          UART_print("             .=@%.     *@=  .%@-    .:*@= -@@@@@@@@@@@@@@@..@%-.  .+-    -%*      #@*.              \r\n");
                          UART_print("             .+@#. ..  *@=  *@=.   .=@@@* *@@@@@@@@@@@@@@@+=@@@*. ...    -%#  ... +@#.  .:.         \r\n");
                          UART_print("             .*@+..-+. *@= .#@:   .*@@@@@+@@@@@@@@@@@@@@@@@@@@@@%.       -%#  :+: -@%:  +%..        \r\n");
                          UART_print("             :%@-..=*. *@=  #@:  .*@@@@@@@@@@@@@@@@@@@@@@@@@@@@@@#..     -%#  -#: .@%-.*@@%=.       \r\n");
                          UART_print("            .-@%:..**. *@= .-+.  -@@@@@@@@@@@@@@@@@@@@@@@@@@@@@@@@+.     -%# .=%- .@@=.=@@%-.       \r\n");
                          UART_print("            .=@#: .##:.*@=      .#@@@@@@@@@@@@@@@@@@@@@@@@@@@@@@@@%:     :%+ .+@=. #@+.*@@%-..      \r\n");
                          UART_print("          .-#@@@#::%%- *@=  ... :%@@@@@@@@@@@@@@@@@@@@@@@@@@@@@@@@%-.        .*@+.:%@@@@@@@#:.      \r\n");
                          UART_print("        .-%@%=-+%@@@@-.+@-  .%..-%@@@@@@@@@@@@@@@@@@@@@@@@@@@@@@@@@=         .#@@@@#+::+@@@%+.      \r\n");
                          UART_print("       .=@@-.. ...*@@=...   .@. -%@@@@@@@@@@@@@@@@@@@@@@@@@@@@@@@@@+.        :@@%=..    .%@@+.      \r\n");
                          UART_print("      .-@@-.-*==...=%@=.    :@- -%@@@@@@@@@@@@@@@@@@@@@@@@@@@@@@@@@+.       =@@+.. +::=. =@@%:      \r\n");
                          UART_print("      .*@@%%%@%%%%%%@@@%%%%%%@@%@@@....:::................::::...#@@%%%%%%%@@@@%%%%@@@%%%%@#:.      \r\n");
                          UART_print("      ..:-------------------------:  .......             .........:-----------------------:..       \r\n");
                          gs.puzzle_step = 0;
                          gs.active_puzzle = 0;
                          gs.state = STATE_INVENTORY;
                          gs.prev_state = STATE_CAVE;
                          UART_print("\r\nPress any key to continue...\r\n");
                      } else {
                          // Prompt next move
                          UART_print("Which pile next? (A/B/C):\r\n> ");
                      }
                  } else {
                      // Wrong
                      gs.fear += 10;
                      gs.fear = clamp(gs.fear, 0, 100);
                      gs.puzzle_step = 0; // reset sequence
                      if (gs.difficulty == 0) {
                          UART_print("Wrong choice! The debris shifts dangerously.\r\n");
                          UART_print("Fear increased. Try again from the start.\r\n");
                          UART_print("Hint: Start with B.\r\n");
                      } else {
                          UART_print("The debris collapses. You scramble back.\r\n");
                          UART_print("Fear increased. Try again from the start.\r\n");
                      }
                      UART_print("Which pile do you move first? (A/B/C):\r\n> ");
                  }
                  check_death_conditions();
              }
              else if (gs.active_puzzle == 2){ // Bunker puzzle
                  char echo[2] = {c, '\0'};
                  UART_print(echo);
                  UART_print("\r\n");
                  const char correct[3] = {'3', '1', '2'};
                  if (c == correct[gs.puzzle_step]) {
                      gs.puzzle_step++;
                      if (gs.puzzle_step == 1) {
                          UART_print("You prime the fuel line. It sputters and catches.\r\n");
                          UART_print("Next step (1/2/3):\r\n> ");
                      }
                      else if (gs.puzzle_step == 2) {
                          UART_print("You connect the battery. The generator hums weakly.\r\n");
                          UART_print("Next step (1/2/3):\r\n> ");
                      }
                      else if (gs.puzzle_step == 3) {
                          // Solved
                          gs.puzzles_solved |= 0x04;
                          UART_print("You route the wiring. The generator roars to life!\r\n");
                          UART_print("Lights flicker on throughout the bunker.\r\n");
                          UART_print("A radio console lights up in the corner.\r\n");
                          UART_print("An automated distress beacon activates.\r\n\r\n");
                          UART_print("You solved the Bunker puzzle!\r\n");
                          UART_print("\r\n");
                          UART_print("                                                                                                    \r\n");
                          UART_print("                                                  ..                                                \r\n");
                          UART_print("                                        ....:=*%%#**#%%*=::...                                      \r\n");
                          UART_print("                                       .=#*+-...     ....-+*%=.                                     \r\n");
                          UART_print("                                      .**..      ...:-++*#%@@@#.                                    \r\n");
                          UART_print("                                     :%+.       .-@@@@@@@@@@@@@%-.                                  \r\n");
                          UART_print("                                   .+%.         .*@@@@@@@@@@@@@@@=.                                 \r\n");
                          UART_print("                             ..:=#%*-.      ....-@@@@@@@@@@@@@@@@@@@%=:...                          \r\n");
                          UART_print("                            .*#+:.:%%%###**+#@@@@@@@@@@@@@@@@@@@@@@@@@@@%:.                         \r\n");
                          UART_print("                          .-%-....%@@@@@@@@@@@@@@@@@@@@@@@@@@@@@@@@@@@@@@%-.                        \r\n");
                          UART_print("                         .+#:   .+@@@@@@@@@%%#############%@@@@@@@@@@@@@@@@+.                       \r\n");
                          UART_print("                        .*+..  .-@@@@@@#:.=%@@@@@@@@@@@@@@%=..#@@@@@@@@@@@@@%.                      \r\n");
                          UART_print("                      .-%=..-*@@@@@@@*.+@@@@@@@@@@@@@@@@@@@@@@*:+@@@@@@@@@@@##=..                   \r\n");
                          UART_print("                   ..=#+.  :%@@@@@@@=-@@@@@@@@@@@@@@@@@@@@@@@@@%==@@@@@@@#-..-#%+..                 \r\n");
                          UART_print("                  .*#-..   :%@@@@@@+-%@@@@@@@@@@@@@@@@@@@@@@@@@@%-*@@@@@@@@@@@@@@@*:.               \r\n");
                          UART_print("                  +#..     :%@@@@@%=*@@@@@@#..............-%%@@@@+.@@@@@@@@@@@@@@@@+..              \r\n");
                          UART_print("                 :%-       -%@@@@@%-*@@@@@@#..............-%@@@@@*.%@@@@@@@@@@@@@@@%:.              \r\n");
                          UART_print("                .+#.       -@@@@%@%=*@%%%%%%#***#*##******%@%%%%%*.#%@@@@@@@@@@@@@@@+.              \r\n");
                          UART_print("              .-#*.      .:#@@@@%%%=*@@%%%%*..............-%%@%%%*.%%@%@@@@@@@@@@@@@@%=.            \r\n");
                          UART_print("            .+%=..      .+%@@@@@@@%-*@@@@@@%**************#@@@@@@*.%@@@@@@@@@@@@@@@@@@@%+.          \r\n");
                          UART_print("          .*%-....     -@@@@@@@@@@%-*@@@@@@@@@@@@@@@@@@@@@@@@@@@@*.%@@@@@@@@@@@@@@@@@@@@*##.        \r\n");
                          UART_print("          =*..       .*@@@@@@@@@@@%-*@@@@@@@@@@@@@@@@@@@@@@@@@@@@*.%@@@@@@@@@@@@@@@@@@@%*.**.       \r\n");
                          UART_print("          ++..       .+@@@@@@@@@@@%-*@@%-.*@@@@@@@@@@@@@@@@@@@@@@*.%@@@@@@@@@@@@@@@%#-:::.+#.       \r\n");
                          UART_print("          *+..       .=%@@@@@@@@@@%-*@@#  .@@@@@@@@@@@@@@@@@@@@@@*.%@@@@@@@@@@@@@@@@@@@@@%##.       \r\n");
                          UART_print("        .-%-..        =%@@@@@@@@@@%-*@@#  .@@@@@@@@@@@@@@@@@@@@@@*.%@@@@@@@@@@@@@@@@@@@@@@@%+.      \r\n");
                          UART_print("       .##.           -%@@@@@@@@@@%-*@@#  .@@@@@@@@@@@@@@@@@@@@@@*.%@@@@@@@@@@@@@@@@@@@@@@@@@#.     \r\n");
                          UART_print("     .-#-.            -%@@@@@@@@@@%-*@@@%#%@@@@@@@@@@@@@@@@@@@@@@*.%@@@@@@@@@@@@@@@@@@@@@@@@@@@=.   \r\n");
                          UART_print("     .#-.             -%@@@@@@@@@@%-*@@@@@@@@@@@@@@@@@@@@@@@@@@@@*.%@@@@@@@@@@@@@@@@@@@@@@@@@@@@:   \r\n");
                          UART_print("    ..:................::::::::::::.*@@@@@@@@@@@@@@@@@@@@@@@@@@@@*.:::::::::::::::::::::::::::::... \r\n");
                          UART_print("  .=@@@@@@@@@@@@@@@@@@@@@@@@@@@@@@%-*@@@@@@@@@@@@@@@@@@@@@@@@@@@@*.%@@@@@@@@@@@@@@@@@@@@@@@@@@@@@@=.\r\n");
                          UART_print("  .=@@@@@@@@@@@@@@@@@@@@@@@@@@@@@@%-*@@@@@@@@@@@@@@@@@@@@@@@@@@@@*.%@@@@@@@@@@@@@@@@@@@@@@@@@@@@@@=.\r\n");
                          gs.puzzle_step = 0;
                          gs.active_puzzle = 0;
                          gs.state = STATE_INVENTORY;
                          gs.prev_state = STATE_BUNKER;
                          UART_print("\r\nPress any key to continue...\r\n");
                      }
                  }
                  else {
                      // Wrong choice
                	  gs.health -= 10;
                	  gs.fear += 10;
                	  gs.health = clamp(gs.health, 0, 100);
                	  gs.fear = clamp(gs.fear, 0, 100);
                      gs.puzzle_step = 0;
                      if (c == '1' || c == '2') {
                          UART_print("Sparks fly as the system shorts out.\r\n");
                          UART_print("You were thrown back by the surge.\r\n");
                      }
                      else {
                          UART_print("Something goes wrong. The generator sputters and dies.\r\n");
                      }
                      if (gs.difficulty == 0) {
                          UART_print("Health and fear affected. Try again.\r\n");
                          UART_print("Hint: Prime the fuel line first.\r\n");
                      }
                      else {
                          UART_print("Health and fear affected. Try again.\r\n");
                      }
                      UART_print("Choose your first step (1/2/3):\r\n> ");
                      check_death_conditions();
                  }
              }
              break;

          default:
              break;
      }

  } /* Game engine END WHILE */

  // Game over
  while(1);
}

void SystemClock_Config(void)
{
  RCC_OscInitTypeDef RCC_OscInitStruct = {0};
  RCC_ClkInitTypeDef RCC_ClkInitStruct = {0};

  /** Configure the main internal regulator output voltage
  */
  if (HAL_PWREx_ControlVoltageScaling(PWR_REGULATOR_VOLTAGE_SCALE1) != HAL_OK)
  {
    Error_Handler();
  }
  /** Initializes the RCC Oscillators according to the specified parameters
  * in the RCC_OscInitTypeDef structure.
  */
  RCC_OscInitStruct.OscillatorType = RCC_OSCILLATORTYPE_HSI;
  RCC_OscInitStruct.HSIState = RCC_HSI_ON;
  RCC_OscInitStruct.HSICalibrationValue = RCC_HSICALIBRATION_DEFAULT;
  RCC_OscInitStruct.PLL.PLLState = RCC_PLL_ON;
  RCC_OscInitStruct.PLL.PLLSource = RCC_PLLSOURCE_HSI;
  RCC_OscInitStruct.PLL.PLLM = 1;
  RCC_OscInitStruct.PLL.PLLN = 10;
  RCC_OscInitStruct.PLL.PLLP = RCC_PLLP_DIV7;
  RCC_OscInitStruct.PLL.PLLQ = RCC_PLLQ_DIV2;
  RCC_OscInitStruct.PLL.PLLR = RCC_PLLR_DIV2;
  if (HAL_RCC_OscConfig(&RCC_OscInitStruct) != HAL_OK)
  {
    Error_Handler();
  }
  /** Initializes the CPU, AHB and APB buses clocks
  */
  RCC_ClkInitStruct.ClockType = RCC_CLOCKTYPE_HCLK|RCC_CLOCKTYPE_SYSCLK
                              |RCC_CLOCKTYPE_PCLK1|RCC_CLOCKTYPE_PCLK2;
  RCC_ClkInitStruct.SYSCLKSource = RCC_SYSCLKSOURCE_PLLCLK;
  RCC_ClkInitStruct.AHBCLKDivider = RCC_SYSCLK_DIV1;
  RCC_ClkInitStruct.APB1CLKDivider = RCC_HCLK_DIV1;
  RCC_ClkInitStruct.APB2CLKDivider = RCC_HCLK_DIV1;

  if (HAL_RCC_ClockConfig(&RCC_ClkInitStruct, FLASH_LATENCY_4) != HAL_OK)
  {
    Error_Handler();
  }
}

static void MX_USART2_UART_Init(void)
{

  huart2.Instance = USART2;
  huart2.Init.BaudRate = 115200;
  huart2.Init.WordLength = UART_WORDLENGTH_8B;
  huart2.Init.StopBits = UART_STOPBITS_1;
  huart2.Init.Parity = UART_PARITY_NONE;
  huart2.Init.Mode = UART_MODE_TX_RX;
  huart2.Init.HwFlowCtl = UART_HWCONTROL_NONE;
  huart2.Init.OverSampling = UART_OVERSAMPLING_16;
  huart2.Init.OneBitSampling = UART_ONE_BIT_SAMPLE_DISABLE;
  huart2.AdvancedInit.AdvFeatureInit = UART_ADVFEATURE_NO_INIT;
  if (HAL_UART_Init(&huart2) != HAL_OK)
  {
    Error_Handler();
  }

}

static void MX_DMA_Init(void)
{

  /* DMA controller clock enable */
  __HAL_RCC_DMA1_CLK_ENABLE();

  /* DMA interrupt init */
  /* DMA1_Channel6_IRQn interrupt configuration */
  HAL_NVIC_SetPriority(DMA1_Channel6_IRQn, 0, 0);
  HAL_NVIC_EnableIRQ(DMA1_Channel6_IRQn);
  /* DMA1_Channel7_IRQn interrupt configuration */
  HAL_NVIC_SetPriority(DMA1_Channel7_IRQn, 0, 0);
  HAL_NVIC_EnableIRQ(DMA1_Channel7_IRQn);

}

static void MX_GPIO_Init(void)
{
  GPIO_InitTypeDef GPIO_InitStruct = {0};

  /* GPIO Ports Clock Enable */
  __HAL_RCC_GPIOC_CLK_ENABLE();
  __HAL_RCC_GPIOH_CLK_ENABLE();
  __HAL_RCC_GPIOA_CLK_ENABLE();
  __HAL_RCC_GPIOB_CLK_ENABLE();

  /*Configure GPIO pin Output Level */
  HAL_GPIO_WritePin(LD2_GPIO_Port, LD2_Pin, GPIO_PIN_RESET);

  /*Configure GPIO pin : B1_Pin */
  GPIO_InitStruct.Pin = B1_Pin;
  GPIO_InitStruct.Mode = GPIO_MODE_IT_FALLING;
  GPIO_InitStruct.Pull = GPIO_NOPULL;
  HAL_GPIO_Init(B1_GPIO_Port, &GPIO_InitStruct);

  /*Configure GPIO pin : LD2_Pin */
  GPIO_InitStruct.Pin = LD2_Pin;
  GPIO_InitStruct.Mode = GPIO_MODE_OUTPUT_PP;
  GPIO_InitStruct.Pull = GPIO_NOPULL;
  GPIO_InitStruct.Speed = GPIO_SPEED_FREQ_LOW;
  HAL_GPIO_Init(LD2_GPIO_Port, &GPIO_InitStruct);

}

/* USER CODE BEGIN 4 */
/* If UART2 has received a byte from the user terminal this function
 * will be called.
 * dataAvail is used to indicate that the rx_buff has received new data and can be checked.
 */
void HAL_UART_RxCpltCallback(UART_HandleTypeDef *huart)
{
  HAL_UART_Receive_IT(&huart2, (uint8_t *)rx_buff, 1); //You need to toggle a breakpoint on this line!
  dataAvail=1;
}
/* USER CODE END 4 */

void Error_Handler(void)
{
  __disable_irq();
  while (1)
  {
  }
}
